# PRU_ICSSG0_IEP0_local register map
Vendor: Texas Instruments
Peripheral module from a debugger description file (folder J7ES).
Registers are 32-bit, read-write, reset 0x0 unless marked. A register's access mark holds for its fields unless they carry their own. Offsets are as the file gives them; lines under a group give offsets from that group; [hi:lo] are bit positions; {n}, {i} and the like mark numbered series; 'fields as' and 'values as' point back to an identical list; <NAME> marks a mode.

## PRU_ICSSG0_IEP0
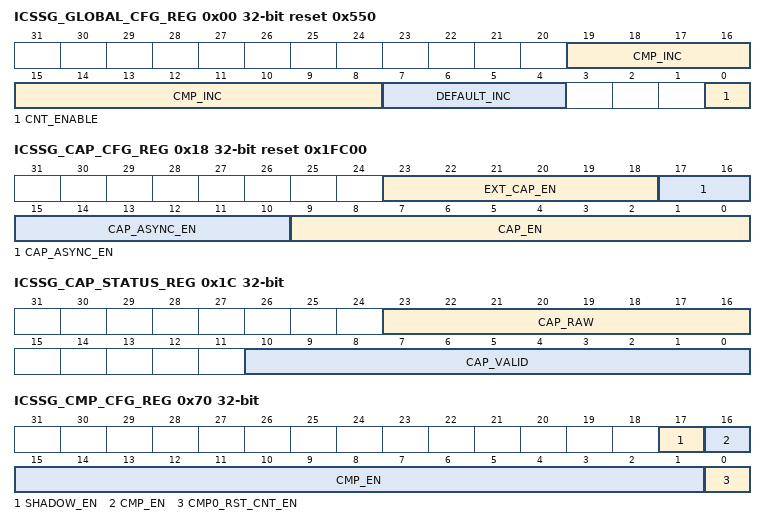
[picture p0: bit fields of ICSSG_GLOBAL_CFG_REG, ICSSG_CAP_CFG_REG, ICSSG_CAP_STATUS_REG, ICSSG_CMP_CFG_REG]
0x00 ICSSG_GLOBAL_CFG_REG reset 0x550 — Global Cfg
  [19:8] CMP_INC, [7:4] DEFAULT_INC, [0] CNT_ENABLE
0x04 ICSSG_GLOBAL_STATUS_REG access not given — Status
  [0] CNT_OVF — (access RW1C)
0x08 ICSSG_COMPEN_REG — Compensation
  [22:0] COMPEN_CNT
0x0C ICSSG_SLOW_COMPEN_REG — Slow Compensation
  [31:0] SLOW_COMPEN_CNT
0x10 ICSSG_COUNT_REG0 — Low Counter
  [31:0] COUNT_LO
0x14 ICSSG_COUNT_REG1 — High Counter
  [31:0] COUNT_HI
0x18 ICSSG_CAP_CFG_REG reset 0x1FC00 — Capture Cfg
  [23:18] EXT_CAP_EN, [17:10] CAP_ASYNC_EN, [9:0] CAP_EN
0x1C ICSSG_CAP_STATUS_REG ro — Capture Status Cfg
  [23:16] CAP_RAW, [10:0] CAP_VALID
{0x20+8i} ICSSG_CAPR{i}_REG0 ro (i=0..6) — Capture Rise{i:02}
  [31:0] CAPR{i}_0
{0x24+8i} ICSSG_CAPR{i}_REG1 ro (i=0..6) — Capture Rise{i+10}
  [31:0] CAPR{i}_1
0x58 ICSSG_CAPF6_REG0 ro — Capture Fall06
  [31:0] CAPF6_0
0x5C ICSSG_CAPF6_REG1 ro — Capture Fall16
  [31:0] CAPF6_1
0x60 ICSSG_CAPR7_REG0 ro — Capture Rise07
  [31:0] CAPR7_0
0x64 ICSSG_CAPR7_REG1 ro — Capture Rise17
  [31:0] CAPR7_1
0x68 ICSSG_CAPF7_REG0 ro — Capture Fall07
  [31:0] CAPF7_0
0x6C ICSSG_CAPF7_REG1 ro — Capture Fall17
  [31:0] CAPF7_1
0x70 ICSSG_CMP_CFG_REG — Capture Cfg
  [17] SHADOW_EN, [16:1] CMP_EN, [0] CMP0_RST_CNT_EN
0x74 ICSSG_CMP_STATUS_REG access not given — Capture Status
  [15:0] CMP_STATUS — (access RW1C)
{0x78+8i} ICSSG_CMP{i}_REG0 (i=0..7) — Compare{i:02}
  [31:0] CMP{i}_0
{0x7C+8i} ICSSG_CMP{i}_REG1 (i=0..7) — Compare{i+10}
  [31:0] CMP{i}_1
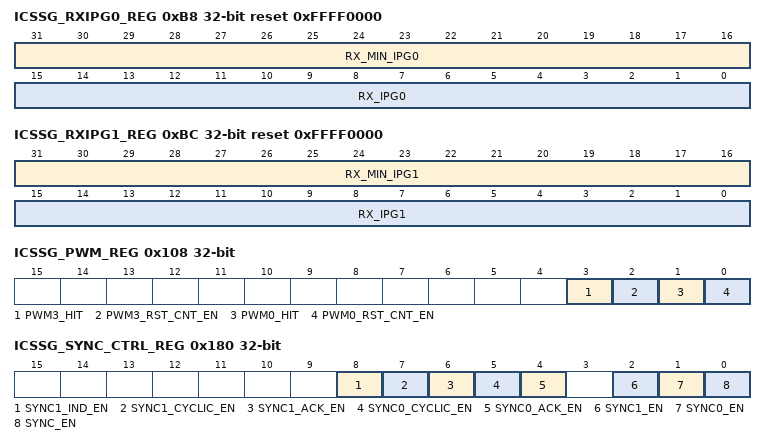
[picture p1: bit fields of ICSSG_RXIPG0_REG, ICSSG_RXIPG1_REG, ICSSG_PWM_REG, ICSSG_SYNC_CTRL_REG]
0xB8 ICSSG_RXIPG0_REG access per field reset 0xFFFF0000 — RXIPG0
  [31:16] RX_MIN_IPG0 rw, [15:0] RX_IPG0 ro
0xBC ICSSG_RXIPG1_REG access per field reset 0xFFFF0000 — RXIPG1
  [31:16] RX_MIN_IPG1 rw, [15:0] RX_IPG1 ro
0xC0 ICSSG_CMP8_REG0 — Compare08
  [31:0] CMP8_0
0xC4 ICSSG_CMP8_REG1 — Compare18
  [31:0] CMP8_1
0xC8 ICSSG_CMP9_REG0 — Compare09
  [31:0] CMP9_0
0xCC ICSSG_CMP9_REG1 — Compare19
  [31:0] CMP9_1
{0x80+8i} ICSSG_CMP{i}_REG0 (i=10..15) — Compare{i:03}
  [31:0] CMP{i}_0
{0x84+8i} ICSSG_CMP{i}_REG1 (i=10..15) — Compare{i+100}
  [31:0] CMP{i}_1
0x100 ICSSG_COUNT_RESET_VAL_REG0 — Low Counter Reset Value
  [31:0] RESET_VAL_0
0x104 ICSSG_COUNT_RESET_VAL_REG1 — Low Counter Reset Value
  [31:0] RESET_VAL_1
0x108 ICSSG_PWM_REG access not given — PWM
  [3] PWM3_HIT — (access RW1C)
  [2] PWM3_RST_CNT_EN rw
  [1] PWM0_HIT — (access RW1C)
  [0] PWM0_RST_CNT_EN rw
{0x10C+8i} ICSSG_CAPR{i}_BI_REG0 ro (i=0..6) — Capture Big Indian Rise{i:02}
  [31:0] CAPR{i}_0
{0x110+8i} ICSSG_CAPR{i}_BI_REG1 ro (i=0..6) — Capture Big Indian Rise{i+10}
  [31:0] CAPR{i}_1
0x144 ICSSG_CAPF6_BI_REG0 ro — Capture Big Indian Fall06
  [31:0] CAPF6_0
0x148 ICSSG_CAPF6_BI_REG1 ro — Capture Big Indian Fall16
  [31:0] CAPF6_1
0x14C ICSSG_CAPR7_BI_REG0 ro — Capture Big Indian Rise07
  [31:0] CAPR7_0
0x150 ICSSG_CAPR7_BI_REG1 ro — Capture Big Indian Rise17
  [31:0] CAPR7_1
0x154 ICSSG_CAPF7_BI_REG0 ro — Capture Big Indian Fall07
  [31:0] CAPF7_0
0x158 ICSSG_CAPF7_BI_REG1 ro — Capture Big Indian Fall17
  [31:0] CAPF7_1
0x180 ICSSG_SYNC_CTRL_REG — Sync Ctrl
  [8] SYNC1_IND_EN, [7] SYNC1_CYCLIC_EN, [6] SYNC1_ACK_EN, [5] SYNC0_CYCLIC_EN, [4] SYNC0_ACK_EN, [2] SYNC1_EN, [1] SYNC0_EN, [0] SYNC_EN
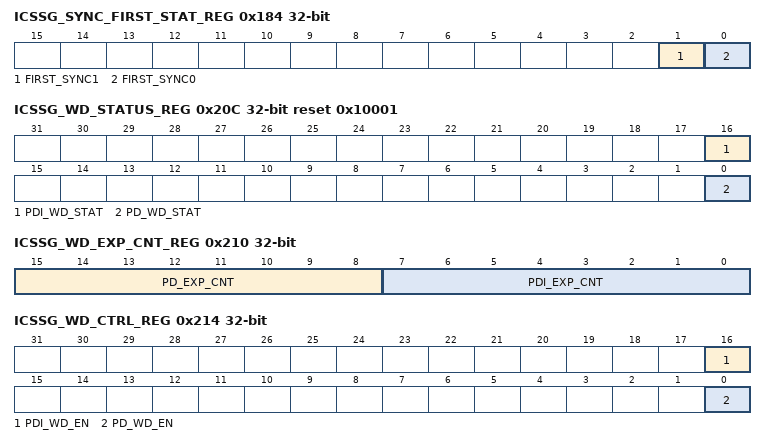
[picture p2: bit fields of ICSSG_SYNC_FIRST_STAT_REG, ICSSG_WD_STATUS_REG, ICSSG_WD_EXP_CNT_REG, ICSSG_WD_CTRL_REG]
0x184 ICSSG_SYNC_FIRST_STAT_REG ro — Sync Ctrl
  [1] FIRST_SYNC1, [0] FIRST_SYNC0
0x188 ICSSG_SYNC0_STAT_REG ro — Sync Ctrl
  [0] SYNC0_PEND
0x18C ICSSG_SYNC1_STAT_REG ro — Sync Ctrl
  [0] SYNC1_PEND
0x190 ICSSG_SYNC_PWIDTH_REG — Sync Ctrl
  [31:0] SYNC_HPW
0x194 ICSSG_SYNC0_PERIOD_REG reset 0x1 — Sync Ctrl
  [31:0] SYNC0_PERIOD
0x198 ICSSG_SYNC1_DELAY_REG — Sync Ctrl
  [31:0] SYNC1_DELAY
0x19C ICSSG_SYNC_START_REG — Sync Ctrl
  [31:0] SYNC_START
0x200 ICSSG_WD_PREDIV_REG reset 0x4E20 — WD
  [15:0] PRE_DIV
0x204 ICSSG_PDI_WD_TIM_REG reset 0x3E8 — WD
  [15:0] PDI_WD_TIME
0x208 ICSSG_PD_WD_TIM_REG reset 0x3E8 — WD
  [15:0] PD_WD_TIME
0x20C ICSSG_WD_STATUS_REG ro reset 0x10001 — WD
  [16] PDI_WD_STAT, [0] PD_WD_STAT
0x210 ICSSG_WD_EXP_CNT_REG — WD
  [15:8] PD_EXP_CNT, [7:0] PDI_EXP_CNT
0x214 ICSSG_WD_CTRL_REG — WD
  [16] PDI_WD_EN, [0] PD_WD_EN
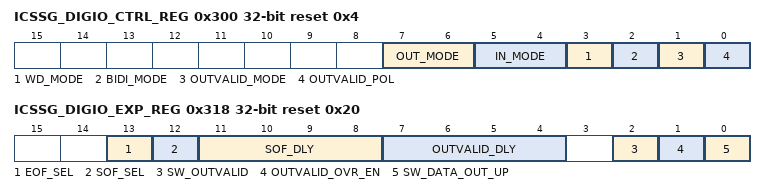
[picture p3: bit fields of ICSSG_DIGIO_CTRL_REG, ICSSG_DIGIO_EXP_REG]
0x300 ICSSG_DIGIO_CTRL_REG access per field reset 0x4 — DIGIO
  [7:6] OUT_MODE rw, [5:4] IN_MODE rw, [3] WD_MODE rw, [2] BIDI_MODE ro, [1] OUTVALID_MODE rw, [0] OUTVALID_POL ro
0x304 ICSSG_DIGIO_STATUS_REG ro — DIGIO
  [31:0] DIGIO_STAT
0x308 ICSSG_DIGIO_DATA_IN_REG ro — DIGIO
  [31:0] DATA_IN
0x30C ICSSG_DIGIO_DATA_IN_RAW_REG ro — DIGIO
  [31:0] DATA_IN_RAW
0x310 ICSSG_DIGIO_DATA_OUT_REG — DIGIO
  [31:0] DATA_OUT
0x314 ICSSG_DIGIO_DATA_OUT_EN_REG — DIGIO
  [31:0] DATA_OUT_EN
0x318 ICSSG_DIGIO_EXP_REG reset 0x20 — DIGIO
  [13] EOF_SEL, [12] SOF_SEL, [11:8] SOF_DLY, [7:4] OUTVALID_DLY, [2] SW_OUTVALID, [1] OUTVALID_OVR_EN, [0] SW_DATA_OUT_UP
